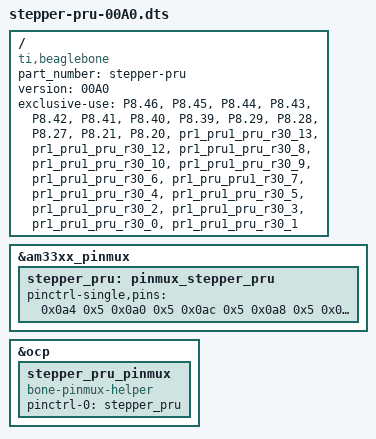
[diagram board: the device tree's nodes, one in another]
/dts-v1/;
/plugin/;

/{
	compatible = "ti,beaglebone", "ti,beaglebone-black";
	part_number = "stepper-pru";
	version = "00A0";
	exclusive-use =	"P8.46",
			"P8.45",
			"P8.44",
			"P8.43",
			"P8.42",
			"P8.41",
			"P8.40",
			"P8.39",
			"P8.29",
			"P8.28",
			"P8.27",
			"P8.21",
                        "P8.20",
			"pr1_pru1_pru_r30_13",
                        "pr1_pru1_pru_r30_12",
			"pr1_pru1_pru_r30_8",
			"pr1_pru1_pru_r30_10",
			"pr1_pru1_pru_r30_9",
			"pr1_pru1_pru_r30_6",
			"pr1_pru_pru1_r30_7",
			"pr1_pru1_pru_r30_4",
			"pr1_pru1_pru_r30_5",
			"pr1_pru1_pru_r30_2",
			"pr1_pru1_pru_r30_3",
			"pr1_pru1_pru_r30_0",
			"pr1_pru1_pru_r30_1";

	fragment@0 {
		target = <&am33xx_pinmux>;

		__overlay__ {
			stepper_pru: pinmux_stepper_pru {
				pinctrl-single,pins = <	0x0a4 0x5
							0x0a0 0x5
							0x0ac 0x5
							0x0a8 0x5
							0x0b4 0x5
							0x0b0 0x5
							0x0bc 0x5
							0x0b8 0x5
							0x0e4 0x5
							0x0e8 0x5
							0x0e0 0x5
							0x080 0x5
                                                        0x084 0x5
				>;
			};
		};
	};

	fragment@1 {
		target = <&ocp>;

		__overlay__ {
			stepper_pru_pinmux {
				compatible = "bone-pinmux-helper";
				status = "okay";
				pinctrl-names = "default";
				pinctrl-0 = <&stepper_pru>;
			};
		};
	};
};
